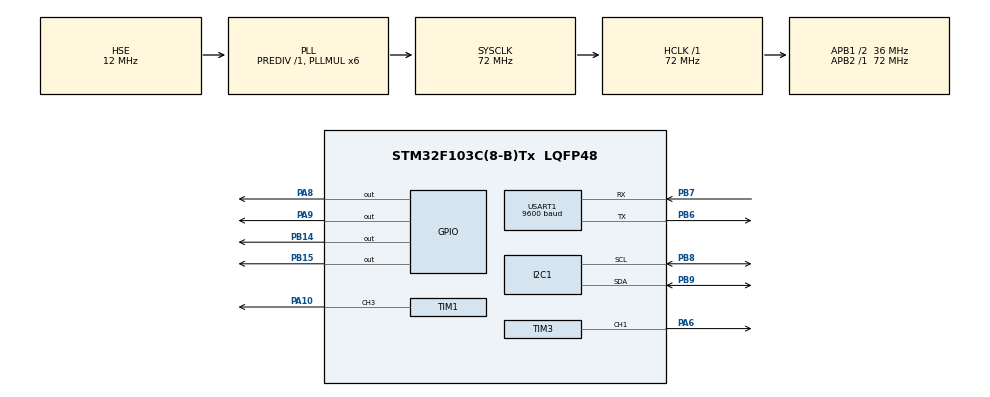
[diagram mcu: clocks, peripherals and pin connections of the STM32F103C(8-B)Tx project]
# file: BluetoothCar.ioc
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I2C1.I2C_Mode=I2C_Fast
Mcu.Family=STM32F1
Mcu.Name=STM32F103C(8-B)Tx
Mcu.Package=LQFP48
NVIC.PriorityGroup=NVIC_PRIORITYGROUP_4
NVIC.TIM3_IRQn=true\:0\:0\:false\:false\:true\:true\:true\:true
NVIC.USART1_IRQn=true\:15\:0\:true\:false\:true\:true\:true\:true
PA10.Signal=S_TIM1_CH3
PA13.Mode=Serial_Wire
PA13.Signal=SYS_JTMS-SWDIO
PA14.Mode=Serial_Wire
PA14.Signal=SYS_JTCK-SWCLK
PA6.Signal=S_TIM3_CH1
PA8.Signal=GPIO_Output
PA9.Signal=GPIO_Output
PB14.Signal=GPIO_Output
PB15.Signal=GPIO_Output
PB6.Mode=Asynchronous
PB6.Signal=USART1_TX
PB7.Mode=Asynchronous
PB7.Signal=USART1_RX
PB8.Mode=I2C
PB8.Signal=I2C1_SCL
PB9.Mode=I2C
PB9.Signal=I2C1_SDA
PD0-OSC_IN.Mode=HSE-External-Oscillator
PD0-OSC_IN.Signal=RCC_OSC_IN
PD1-OSC_OUT.Mode=HSE-External-Oscillator
PD1-OSC_OUT.Signal=RCC_OSC_OUT
ProjectManager.HeapSize=0x200
ProjectManager.StackSize=0x400
ProjectManager.TargetToolchain=STM32CubeIDE
RCC.AHBFreq_Value=72000000
RCC.APB1CLKDivider=RCC_HCLK_DIV2
RCC.APB1Freq_Value=36000000
RCC.APB1TimFreq_Value=72000000
RCC.APB2Freq_Value=72000000
RCC.APB2TimFreq_Value=72000000
RCC.HCLKFreq_Value=72000000
RCC.HSE_VALUE=12000000
RCC.PLLMUL=RCC_PLL_MUL6
RCC.PLLSourceVirtual=RCC_PLLSOURCE_HSE
RCC.SYSCLKFreq_VALUE=72000000
RCC.SYSCLKSource=RCC_SYSCLKSOURCE_PLLCLK
RCC.USBFreq_Value=72000000
SH.S_TIM1_CH3.0=TIM1_CH3,PWM Generation3 CH3
SH.S_TIM3_CH1.0=TIM3_CH1,PWM Generation1 CH1
TIM1.Channel-PWM\ Generation3\ CH3=TIM_CHANNEL_3
TIM1.OCFastMode_PWM-PWM\ Generation3\ CH3=TIM_OCFAST_ENABLE
TIM1.Period=100
TIM1.Prescaler=72-1
TIM3.Channel-PWM\ Generation1\ CH1=TIM_CHANNEL_1
TIM3.OCFastMode_PWM-PWM\ Generation1\ CH1=TIM_OCFAST_ENABLE
TIM3.Period=100
TIM3.Prescaler=72-1
USART1.BaudRate=9600
USART1.VirtualMode=VM_ASYNC
VP_TIM1_VS_ClockSourceINT.Mode=Internal
VP_TIM3_VS_ClockSourceINT.Mode=Internal
board=custom

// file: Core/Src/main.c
/* USER CODE BEGIN Header */
/**
  ******************************************************************************
  * @file           : main.c
  * @brief          : Main program body
  ******************************************************************************
  * @attention
  *
  * Copyright (c) 2022 STMicroelectronics.
  * All rights reserved.
  *
  * This software is licensed under terms that can be found in the LICENSE file
  * in the root directory of this software component.
  * If no LICENSE file comes with this software, it is provided AS-IS.
  *
  ******************************************************************************
  */
/* USER CODE END Header */
#include "main.h"
#include "ssd1306.h"
#include "stm32f1xx_hal_conf.h"
#include "stm32f1xx_it.h"

I2C_HandleTypeDef hi2c1;

TIM_HandleTypeDef htim1;
TIM_HandleTypeDef htim3;

UART_HandleTypeDef huart1;

/* USER CODE BEGIN PV */
uint8_t r;

const unsigned char photo1[] = {
	0x00 , 0x00 , 0x00 , 0x00 , 0x00 , 0x00 , 0x00 , 0x00 , 0x00 , 0xc0 , 0x00 , 0x00 , 0x00 , 0x00 , 0x00 , 0x00 ,
	0x00 , 0x00 , 0x00 , 0x00 , 0x00 , 0x00 , 0x00 , 0x00 , 0x01 , 0x20 , 0x00 , 0x00 , 0x00 , 0x00 , 0x00 , 0x00 ,
	0x00 , 0x00 , 0x00 , 0x00 , 0x00 , 0x00 , 0x00 , 0x00 , 0x02 , 0x10 , 0x00 , 0x00 , 0x00 , 0x00 , 0x00 , 0x00 ,
	0x00 , 0x00 , 0x00 , 0x00 , 0x00 , 0x00 , 0x00 , 0x00 , 0x04 , 0x10 , 0x00 , 0x00 , 0x00 , 0x00 , 0x00 , 0x00 ,
	0x00 , 0x00 , 0x00 , 0x00 , 0x00 , 0x00 , 0x00 , 0x00 , 0x78 , 0x08 , 0x00 , 0x00 , 0x00 , 0x00 , 0x00 , 0x00 ,
	0x00 , 0x00 , 0x00 , 0x00 , 0x00 , 0x00 , 0x00 , 0x07 , 0x80 , 0x08 , 0x00 , 0x00 , 0x00 , 0x00 , 0x00 , 0x00 ,
	0x00 , 0x00 , 0x00 , 0x00 , 0x00 , 0x00 , 0x00 , 0x18 , 0x00 , 0x04 , 0x00 , 0x00 , 0x00 , 0x00 , 0x00 , 0x00 ,
	0x00 , 0x00 , 0x00 , 0x00 , 0x00 , 0x00 , 0x18 , 0x20 , 0x00 , 0x02 , 0x00 , 0x00 , 0x00 , 0x00 , 0x00 , 0x07 ,
	0x00 , 0x00 , 0x00 , 0x00 , 0x00 , 0x00 , 0x26 , 0x40 , 0x00 , 0x01 , 0x9e , 0x00 , 0x00 , 0x00 , 0x00 , 0x78 ,
	0x00 , 0x00 , 0x00 , 0x00 , 0x00 , 0x00 , 0x41 , 0x80 , 0x00 , 0x00 , 0x61 , 0x00 , 0x00 , 0x00 , 0x07 , 0x80 ,
	0x00 , 0x00 , 0x00 , 0x00 , 0x00 , 0x00 , 0x40 , 0x00 , 0x00 , 0x00 , 0x24 , 0x80 , 0x00 , 0x00 , 0xf8 , 0x00 ,
	0x00 , 0x00 , 0x00 , 0x00 , 0x00 , 0x00 , 0x40 , 0x00 , 0x00 , 0x00 , 0x51 , 0x80 , 0x00 , 0x1f , 0x00 , 0x00 ,
	0x00 , 0x00 , 0x00 , 0x00 , 0x00 , 0x00 , 0x40 , 0x00 , 0x00 , 0x18 , 0x4c , 0x80 , 0x01 , 0xe0 , 0x00 , 0x00 ,
	0x00 , 0x00 , 0x00 , 0x00 , 0x00 , 0x00 , 0x20 , 0x00 , 0x00 , 0x18 , 0x8c , 0x80 , 0x1e , 0x00 , 0x00 , 0x00 ,
	0x00 , 0x00 , 0x00 , 0x00 , 0x00 , 0x00 , 0x20 , 0x00 , 0x00 , 0x00 , 0x80 , 0x81 , 0xe0 , 0x00 , 0x00 , 0x00 ,
	0x00 , 0x00 , 0x00 , 0x00 , 0x00 , 0x00 , 0x20 , 0x03 , 0x00 , 0x40 , 0x81 , 0x1e , 0x00 , 0x00 , 0x00 , 0x00 ,
	0x00 , 0x00 , 0x00 , 0x00 , 0x00 , 0x00 , 0x10 , 0x03 , 0x13 , 0xc0 , 0x01 , 0xe0 , 0x00 , 0x00 , 0x00 , 0x00 ,
	0x00 , 0x00 , 0x00 , 0x00 , 0x00 , 0x00 , 0x10 , 0x00 , 0x0c , 0x00 , 0x0e , 0x00 , 0x00 , 0x00 , 0x00 , 0x00 ,
	0x00 , 0x00 , 0x00 , 0x00 , 0x00 , 0x00 , 0x20 , 0x00 , 0x00 , 0x03 , 0xf0 , 0x00 , 0x00 , 0x00 , 0x00 , 0x00 ,
	0x00 , 0x00 , 0x00 , 0x00 , 0x00 , 0x00 , 0x20 , 0x00 , 0x00 , 0x7c , 0x00 , 0x00 , 0x00 , 0x00 , 0x00 , 0x00 ,
	0x00 , 0x00 , 0x00 , 0x00 , 0x00 , 0x00 , 0x40 , 0x00 , 0x07 , 0x80 , 0x00 , 0x00 , 0x00 , 0x00 , 0x00 , 0x00 ,
	0x00 , 0x00 , 0x00 , 0x00 , 0x00 , 0x00 , 0x40 , 0x00 , 0x38 , 0x00 , 0x00 , 0x00 , 0x00 , 0x00 , 0x00 , 0x00 ,
	0x00 , 0x00 , 0x00 , 0x00 , 0x00 , 0x00 , 0x40 , 0x00 , 0x40 , 0x00 , 0x00 , 0x00 , 0x00 , 0x00 , 0x00 , 0x00 ,
	0x00 , 0x00 , 0x00 , 0x00 , 0x00 , 0x00 , 0x80 , 0x00 , 0x20 , 0x00 , 0x00 , 0x00 , 0x00 , 0x00 , 0x00 , 0x00 ,
	0x00 , 0x00 , 0x00 , 0x00 , 0x00 , 0x00 , 0x9f , 0x80 , 0x20 , 0x00 , 0x00 , 0x00 , 0x00 , 0x00 , 0x00 , 0x00 ,
	0x00 , 0x00 , 0x00 , 0x00 , 0x00 , 0x01 , 0xe0 , 0x60 , 0x20 , 0x00 , 0x00 , 0x00 , 0x00 , 0x00 , 0x00 , 0x00 ,
	0x00 , 0x00 , 0x00 , 0x00 , 0x00 , 0x3e , 0x00 , 0x18 , 0x20 , 0x00 , 0x00 , 0x00 , 0x00 , 0x00 , 0x00 , 0x00 ,
	0x00 , 0x00 , 0x00 , 0x00 , 0x07 , 0xc0 , 0x7f , 0x07 , 0xc0 , 0x00 , 0x00 , 0x00 , 0x00 , 0x00 , 0x00 , 0x00 ,
	0x00 , 0x00 , 0x00 , 0x00 , 0x78 , 0x00 , 0x7f , 0x80 , 0x00 , 0x00 , 0x00 , 0x00 , 0x00 , 0x00 , 0x00 , 0x00 ,
	0x00 , 0x00 , 0x00 , 0x07 , 0x80 , 0x00 , 0x7f , 0x80 , 0x00 , 0x00 , 0x00 , 0x00 , 0x00 , 0x00 , 0x00 , 0x00 ,
	0x00 , 0x00 , 0x00 , 0x78 , 0x00 , 0x00 , 0x7e , 0x00 , 0x00 , 0x00 , 0x00 , 0x00 , 0x00 , 0x00 , 0x00 , 0x00 ,
	0x00 , 0x00 , 0x07 , 0x80 , 0x00 , 0x00 , 0x00 , 0x00 , 0xf0 , 0x00 , 0x00 , 0x00 , 0x00 , 0x00 , 0x00 , 0x00 ,
	0x00 , 0x00 , 0x78 , 0x00 , 0x00 , 0x00 , 0x00 , 0x70 , 0xf8 , 0x00 , 0x00 , 0x00 , 0x00 , 0x00 , 0x00 , 0x00 ,
	0x00 , 0x07 , 0x80 , 0x00 , 0x00 , 0x00 , 0x00 , 0xf0 , 0xfc , 0x00 , 0x00 , 0x00 , 0x00 , 0x00 , 0x00 , 0x00 ,
	0x00 , 0x78 , 0x00 , 0x00 , 0x00 , 0x00 , 0x01 , 0xf0 , 0xfe , 0x00 , 0x00 , 0x00 , 0x00 , 0x00 , 0x00 , 0x00 ,
	0x07 , 0x80 , 0x00 , 0x00 , 0x00 , 0x00 , 0x03 , 0xe0 , 0xff , 0x00 , 0x00 , 0x00 , 0x00 , 0x00 , 0x00 , 0x00 ,
	0x78 , 0x00 , 0x00 , 0x00 , 0x00 , 0x00 , 0x07 , 0xe0 , 0xff , 0x00 , 0x00 , 0x00 , 0x00 , 0x00 , 0x00 , 0x00 ,
	0x80 , 0x00 , 0x00 , 0x00 , 0x00 , 0x00 , 0x07 , 0xe0 , 0xfc , 0x00 , 0x00 , 0x00 , 0x00 , 0x00 , 0x00 , 0x00 ,
	0x00 , 0x00 , 0x00 , 0x00 , 0x00 , 0x00 , 0x03 , 0xc0 , 0xf0 , 0x00 , 0x00 , 0x00 , 0x00 , 0x00 , 0x00 , 0x00 ,
	0x00 , 0x00 , 0x00 , 0x00 , 0x00 , 0x00 , 0x00 , 0xc0 , 0xc0 , 0x00 , 0x00 , 0x00 , 0x00 , 0x00 , 0x00 , 0x00 ,
};
const unsigned char photo2[] = {
	0x00 , 0x00 , 0x00 , 0x00 , 0x00 , 0x00 , 0x00 , 0x00 , 0x00 , 0xc0 , 0x00 , 0x00 , 0x00 , 0x00 , 0x00 , 0x00 ,
	0x00 , 0x00 , 0x00 , 0x00 , 0x00 , 0x00 , 0x00 , 0x00 , 0x01 , 0x20 , 0x00 , 0x00 , 0x00 , 0x00 , 0x00 , 0x00 ,
	0x00 , 0x00 , 0x00 , 0x00 , 0x00 , 0x00 , 0x00 , 0x00 , 0x02 , 0x10 , 0x00 , 0x00 , 0x00 , 0x00 , 0x00 , 0x00 ,
	0x00 , 0x00 , 0x00 , 0x00 , 0x00 , 0x00 , 0x00 , 0x00 , 0x04 , 0x10 , 0x03 , 0xc0 , 0x00 , 0x00 , 0x00 , 0x00 ,
	0x00 , 0x00 , 0x00 , 0x00 , 0x00 , 0x00 , 0x00 , 0x00 , 0x78 , 0x08 , 0x03 , 0xc0 , 0x00 , 0x00 , 0x00 , 0x00 ,
	0x00 , 0x00 , 0x00 , 0x00 , 0x00 , 0x00 , 0x00 , 0x07 , 0x80 , 0x08 , 0x03 , 0xc0 , 0x00 , 0x00 , 0x00 , 0x00 ,
	0x00 , 0x00 , 0x00 , 0x00 , 0x00 , 0x00 , 0x00 , 0x18 , 0x00 , 0x04 , 0x03 , 0xc0 , 0x00 , 0x00 , 0x00 , 0x00 ,
	0x00 , 0x00 , 0x00 , 0x00 , 0x00 , 0x00 , 0x18 , 0x20 , 0x00 , 0x02 , 0x03 , 0xc1 , 0x80 , 0x00 , 0x00 , 0x07 ,
	0x00 , 0x00 , 0x00 , 0x00 , 0x00 , 0x00 , 0x26 , 0x40 , 0x00 , 0x01 , 0x83 , 0xc3 , 0xc0 , 0x00 , 0x00 , 0x78 ,
	0x00 , 0x00 , 0x00 , 0x00 , 0x00 , 0x00 , 0x41 , 0x80 , 0x00 , 0x00 , 0x43 , 0x87 , 0xc0 , 0x00 , 0x07 , 0x80 ,
	0x00 , 0x00 , 0x00 , 0x00 , 0x00 , 0x00 , 0x40 , 0x00 , 0x00 , 0x00 , 0x21 , 0x8f , 0xe0 , 0x00 , 0xf8 , 0x00 ,
	0x00 , 0x00 , 0x00 , 0x00 , 0x00 , 0x00 , 0x40 , 0x00 , 0x00 , 0x00 , 0x10 , 0x1f , 0xe0 , 0x1f , 0x00 , 0x00 ,
	0x00 , 0x00 , 0x00 , 0x00 , 0x00 , 0x00 , 0x40 , 0x00 , 0x00 , 0x18 , 0x08 , 0x1f , 0x81 , 0xe0 , 0x00 , 0x00 ,
	0x00 , 0x00 , 0x00 , 0x00 , 0x00 , 0x00 , 0x20 , 0x00 , 0x00 , 0x18 , 0x04 , 0x1c , 0x1e , 0x00 , 0x00 , 0x00 ,
	0x00 , 0x00 , 0x00 , 0x00 , 0x00 , 0x00 , 0x20 , 0x00 , 0x00 , 0x00 , 0x02 , 0x01 , 0xe0 , 0x00 , 0x00 , 0x00 ,
	0x00 , 0x00 , 0x00 , 0x00 , 0x00 , 0x00 , 0x20 , 0x73 , 0x00 , 0x40 , 0x01 , 0x1e , 0x00 , 0x00 , 0x00 , 0x00 ,
	0x00 , 0x00 , 0x00 , 0x00 , 0x00 , 0x00 , 0x10 , 0xab , 0x13 , 0xc0 , 0x01 , 0xe0 , 0x00 , 0x00 , 0x00 , 0x00 ,
	0x00 , 0x00 , 0x00 , 0x00 , 0x00 , 0x00 , 0x11 , 0x08 , 0x0c , 0x00 , 0x00 , 0x80 , 0x00 , 0x00 , 0x00 , 0x00 ,
	0x00 , 0x00 , 0x00 , 0x00 , 0x00 , 0x00 , 0x21 , 0x94 , 0x00 , 0x03 , 0x00 , 0xbf , 0xe0 , 0x00 , 0x00 , 0x00 ,
	0x00 , 0x00 , 0x00 , 0x00 , 0x00 , 0x00 , 0x22 , 0x64 , 0x00 , 0x7c , 0xc0 , 0xbf , 0xe0 , 0x00 , 0x00 , 0x00 ,
	0x00 , 0x00 , 0x00 , 0x00 , 0x00 , 0x00 , 0x42 , 0x64 , 0x07 , 0x80 , 0x3f , 0x3f , 0xc0 , 0x00 , 0x00 , 0x00 ,
	0x00 , 0x00 , 0x00 , 0x00 , 0x00 , 0x00 , 0x40 , 0x04 , 0x38 , 0x00 , 0x00 , 0x3f , 0xc0 , 0x00 , 0x00 , 0x00 ,
	0x00 , 0x00 , 0x00 , 0x00 , 0x00 , 0x00 , 0x40 , 0x0f , 0xc0 , 0x00 , 0x00 , 0x1f , 0x80 , 0x00 , 0x00 , 0x00 ,
	0x00 , 0x00 , 0x00 , 0x00 , 0x00 , 0x00 , 0x80 , 0x70 , 0x00 , 0x00 , 0x00 , 0x0f , 0x80 , 0x00 , 0x00 , 0x00 ,
	0x00 , 0x00 , 0x00 , 0x00 , 0x00 , 0x00 , 0x9f , 0x80 , 0x00 , 0x00 , 0x00 , 0x07 , 0x00 , 0x00 , 0x00 , 0x00 ,
	0x00 , 0x00 , 0x00 , 0x00 , 0x00 , 0x01 , 0xe0 , 0x00 , 0x00 , 0x00 , 0x00 , 0x03 , 0x00 , 0x00 , 0x00 , 0x00 ,
	0x00 , 0x00 , 0x00 , 0x00 , 0x00 , 0x3e , 0x00 , 0x00 , 0x00 , 0x00 , 0x00 , 0x00 , 0x00 , 0x00 , 0x00 , 0x00 ,
	0x00 , 0x00 , 0x00 , 0x00 , 0x07 , 0xc0 , 0x00 , 0x00 , 0x00 , 0x00 , 0x00 , 0x00 , 0x00 , 0x00 , 0x00 , 0x00 ,
	0x00 , 0x00 , 0x00 , 0x00 , 0x78 , 0x00 , 0x00 , 0x00 , 0x00 , 0x00 , 0x00 , 0x00 , 0x00 , 0x00 , 0x00 , 0x00 ,
	0x00 , 0x00 , 0x00 , 0x07 , 0x80 , 0x00 , 0x00 , 0x00 , 0x00 , 0x00 , 0x00 , 0x00 , 0x00 , 0x00 , 0x00 , 0x00 ,
	0x00 , 0x00 , 0x00 , 0x78 , 0x00 , 0x00 , 0x00 , 0x00 , 0x00 , 0x00 , 0x00 , 0x00 , 0x00 , 0x00 , 0x00 , 0x00 ,
	0x00 , 0x00 , 0x07 , 0x80 , 0x00 , 0x00 , 0x00 , 0x00 , 0x00 , 0x00 , 0x00 , 0x00 , 0x00 , 0x00 , 0x00 , 0x00 ,
	0x00 , 0x00 , 0x78 , 0x00 , 0x00 , 0x00 , 0x00 , 0x00 , 0x00 , 0x00 , 0x00 , 0x00 , 0x00 , 0x00 , 0x00 , 0x00 ,
	0x00 , 0x07 , 0x80 , 0x00 , 0x00 , 0x00 , 0x00 , 0x00 , 0x00 , 0x00 , 0x00 , 0x00 , 0x00 , 0x00 , 0x00 , 0x00 ,
	0x00 , 0x78 , 0x00 , 0x00 , 0x00 , 0x00 , 0x00 , 0x00 , 0x00 , 0x00 , 0x00 , 0x00 , 0x00 , 0x00 , 0x00 , 0x00 ,
	0x07 , 0x80 , 0x00 , 0x00 , 0x00 , 0x00 , 0x00 , 0x00 , 0x00 , 0x00 , 0x00 , 0x00 , 0x00 , 0x00 , 0x00 , 0x00 ,
	0x78 , 0x00 , 0x00 , 0x00 , 0x00 , 0x00 , 0x00 , 0x00 , 0x00 , 0x00 , 0x00 , 0x00 , 0x00 , 0x00 , 0x00 , 0x00 ,
	0x80 , 0x00 , 0x00 , 0x00 , 0x00 , 0x00 , 0x00 , 0x00 , 0x00 , 0x00 , 0x00 , 0x00 , 0x00 , 0x00 , 0x00 , 0x00 ,
	0x00 , 0x00 , 0x00 , 0x00 , 0x00 , 0x00 , 0x00 , 0x00 , 0x00 , 0x00 , 0x00 , 0x00 , 0x00 , 0x00 , 0x00 , 0x00 ,
	0x00 , 0x00 , 0x00 , 0x00 , 0x00 , 0x00 , 0x00 , 0x00 , 0x00 , 0x00 , 0x00 , 0x00 , 0x00 , 0x00 , 0x00 , 0x00 ,
};
const unsigned char photo3[] = {
	0x00 , 0x00 , 0x00 , 0x00 , 0x00 , 0x00 , 0x00 , 0x00 , 0x00 , 0xc0 , 0x00 , 0x00 , 0x00 , 0x00 , 0x00 , 0x00 ,
	0x00 , 0x00 , 0x00 , 0x00 , 0x00 , 0x00 , 0x00 , 0x00 , 0x01 , 0x20 , 0x00 , 0x00 , 0x00 , 0x00 , 0x00 , 0x00 ,
	0x00 , 0x00 , 0x00 , 0x00 , 0x00 , 0x00 , 0x00 , 0x00 , 0x02 , 0x10 , 0x00 , 0x00 , 0x00 , 0x00 , 0x00 , 0x00 ,
	0x00 , 0x00 , 0x00 , 0x00 , 0x00 , 0x00 , 0x00 , 0x00 , 0x04 , 0x10 , 0x00 , 0x00 , 0x00 , 0x00 , 0x00 , 0x00 ,
	0x00 , 0x00 , 0x00 , 0x00 , 0x00 , 0x00 , 0x00 , 0x00 , 0x78 , 0x08 , 0x00 , 0x00 , 0x00 , 0x00 , 0x00 , 0x00 ,
	0x00 , 0x00 , 0x00 , 0x00 , 0x00 , 0x00 , 0x00 , 0x07 , 0x80 , 0x08 , 0x00 , 0x00 , 0x00 , 0x00 , 0x00 , 0x00 ,
	0x00 , 0x00 , 0x00 , 0x00 , 0x00 , 0x00 , 0x00 , 0x18 , 0x00 , 0x04 , 0x00 , 0x00 , 0x00 , 0x00 , 0x00 , 0x00 ,
	0x00 , 0x00 , 0x00 , 0x00 , 0x00 , 0x00 , 0x18 , 0x20 , 0x00 , 0x02 , 0x00 , 0x00 , 0x00 , 0x00 , 0x00 , 0x07 ,
	0x00 , 0x00 , 0x00 , 0x00 , 0x00 , 0x00 , 0x26 , 0x40 , 0x00 , 0x01 , 0x80 , 0x00 , 0x00 , 0x00 , 0x00 , 0x78 ,
	0x00 , 0x00 , 0x00 , 0x00 , 0x00 , 0x00 , 0x41 , 0x80 , 0x00 , 0x00 , 0x40 , 0x00 , 0x00 , 0x00 , 0x07 , 0x80 ,
	0x00 , 0x00 , 0x00 , 0x00 , 0x00 , 0x00 , 0x40 , 0x00 , 0x00 , 0x00 , 0x20 , 0x00 , 0x00 , 0x00 , 0xf8 , 0x00 ,
	0x00 , 0x00 , 0x00 , 0x00 , 0x00 , 0x00 , 0x40 , 0x00 , 0x00 , 0x00 , 0x10 , 0x00 , 0x00 , 0x1f , 0x00 , 0x00 ,
	0x00 , 0x00 , 0x00 , 0x00 , 0x00 , 0x00 , 0x40 , 0x00 , 0x00 , 0x18 , 0x08 , 0x00 , 0x01 , 0xe0 , 0x00 , 0x00 ,
	0x00 , 0x00 , 0x00 , 0x00 , 0x00 , 0x00 , 0x20 , 0x00 , 0x00 , 0x18 , 0x04 , 0x00 , 0x1e , 0x00 , 0x00 , 0x00 ,
	0x00 , 0x00 , 0x00 , 0x00 , 0x00 , 0x00 , 0x20 , 0x00 , 0x00 , 0x03 , 0xc2 , 0x01 , 0xe0 , 0x00 , 0x00 , 0x00 ,
	0x00 , 0x00 , 0x00 , 0x00 , 0x00 , 0x00 , 0x20 , 0x03 , 0x00 , 0x43 , 0xc1 , 0x1e , 0x00 , 0x00 , 0x00 , 0x00 ,
	0x00 , 0x00 , 0x00 , 0x00 , 0x00 , 0x00 , 0x10 , 0x03 , 0x13 , 0xc0 , 0x01 , 0xe0 , 0x00 , 0x00 , 0x00 , 0x00 ,
	0x00 , 0x00 , 0x00 , 0x00 , 0x00 , 0x00 , 0x10 , 0x00 , 0x0c , 0x00 , 0x00 , 0x80 , 0x00 , 0x00 , 0x00 , 0x00 ,
	0x00 , 0x00 , 0x00 , 0x00 , 0x00 , 0x00 , 0x20 , 0x1e , 0x00 , 0x03 , 0x00 , 0x80 , 0x00 , 0x00 , 0x00 , 0x00 ,
	0x00 , 0x00 , 0x00 , 0x00 , 0x00 , 0x00 , 0x20 , 0x1e , 0x00 , 0x7c , 0xc0 , 0x80 , 0x00 , 0x00 , 0x00 , 0x00 ,
	0x00 , 0x00 , 0x00 , 0x00 , 0x00 , 0x00 , 0x40 , 0x00 , 0x07 , 0x80 , 0x3f , 0x00 , 0x00 , 0x00 , 0x00 , 0x00 ,
	0x00 , 0x00 , 0x00 , 0x00 , 0x00 , 0x00 , 0x40 , 0x00 , 0x38 , 0x00 , 0x00 , 0x00 , 0x00 , 0x00 , 0x00 , 0x00 ,
	0x00 , 0x00 , 0x00 , 0x00 , 0x00 , 0x00 , 0x40 , 0x00 , 0x40 , 0x00 , 0x00 , 0x00 , 0x00 , 0x00 , 0x00 , 0x00 ,
	0x00 , 0x00 , 0x00 , 0x00 , 0x00 , 0x00 , 0x80 , 0x00 , 0x20 , 0x00 , 0x00 , 0x00 , 0x00 , 0x00 , 0x00 , 0x00 ,
	0x00 , 0x00 , 0x00 , 0x00 , 0x00 , 0x00 , 0x9f , 0x80 , 0x20 , 0x00 , 0x00 , 0x00 , 0x00 , 0x00 , 0x00 , 0x00 ,
	0x00 , 0x00 , 0x00 , 0x00 , 0x00 , 0x01 , 0xe0 , 0x60 , 0x20 , 0x00 , 0x00 , 0x00 , 0x00 , 0x00 , 0x00 , 0x00 ,
	0x00 , 0x00 , 0x00 , 0x00 , 0x00 , 0x3e , 0x00 , 0x18 , 0x20 , 0x00 , 0x00 , 0x00 , 0x00 , 0x00 , 0x00 , 0x00 ,
	0x00 , 0x00 , 0x00 , 0x00 , 0x07 , 0xc0 , 0x00 , 0x07 , 0xc0 , 0x00 , 0x00 , 0x00 , 0x00 , 0x00 , 0x00 , 0x00 ,
	0x00 , 0x00 , 0x00 , 0x00 , 0x78 , 0x00 , 0x00 , 0x00 , 0x00 , 0x00 , 0x00 , 0x00 , 0x00 , 0x00 , 0x00 , 0x00 ,
	0x00 , 0x00 , 0x00 , 0x07 , 0x80 , 0x00 , 0x00 , 0x00 , 0x00 , 0x00 , 0x00 , 0x00 , 0x00 , 0x00 , 0x00 , 0x00 ,
	0x00 , 0x00 , 0x00 , 0x78 , 0x00 , 0x00 , 0x00 , 0x00 , 0x00 , 0x00 , 0x00 , 0x00 , 0x00 , 0x00 , 0x00 , 0x00 ,
	0x00 , 0x00 , 0x07 , 0x80 , 0x00 , 0x00 , 0x00 , 0x00 , 0x00 , 0x00 , 0x00 , 0x00 , 0x00 , 0x00 , 0x00 , 0x00 ,
	0x00 , 0x00 , 0x78 , 0x00 , 0x00 , 0x00 , 0x00 , 0x00 , 0x00 , 0x00 , 0x00 , 0x00 , 0x00 , 0x00 , 0x00 , 0x00 ,
	0x00 , 0x07 , 0x80 , 0x00 , 0x00 , 0x00 , 0x00 , 0x00 , 0x00 , 0x00 , 0x00 , 0x00 , 0x00 , 0x00 , 0x00 , 0x00 ,
	0x00 , 0x78 , 0x00 , 0x00 , 0x00 , 0x00 , 0x00 , 0x00 , 0x00 , 0x00 , 0x00 , 0x00 , 0x00 , 0x00 , 0x00 , 0x00 ,
	0x07 , 0x80 , 0x00 , 0x00 , 0x00 , 0x00 , 0x00 , 0x00 , 0x00 , 0x00 , 0x00 , 0x00 , 0x00 , 0x00 , 0x00 , 0x00 ,
	0x78 , 0x00 , 0x00 , 0x00 , 0x00 , 0x00 , 0x00 , 0x00 , 0x00 , 0x00 , 0x00 , 0x00 , 0x00 , 0x00 , 0x00 , 0x00 ,
	0x80 , 0x00 , 0x00 , 0x00 , 0x00 , 0x00 , 0x00 , 0x00 , 0x00 , 0x00 , 0x00 , 0x00 , 0x00 , 0x00 , 0x00 , 0x00 ,
	0x00 , 0x00 , 0x00 , 0x00 , 0x00 , 0x00 , 0x00 , 0x00 , 0x00 , 0x00 , 0x00 , 0x00 , 0x00 , 0x00 , 0x00 , 0x00 ,
	0x00 , 0x00 , 0x00 , 0x00 , 0x00 , 0x00 , 0x00 , 0x00 , 0x00 , 0x00 , 0x00 , 0x00 , 0x00 , 0x00 , 0x00 , 0x00 ,
};
const unsigned char photo4[] = {
	0x00 , 0x00 , 0x00 , 0x00 , 0x00 , 0x00 , 0x00 , 0x00 , 0x00 , 0x00 , 0x00 , 0x00 , 0x00 , 0x00 , 0x00 , 0x00 ,
	0x00 , 0x00 , 0x00 , 0x00 , 0x00 , 0x00 , 0x00 , 0x00 , 0x00 , 0xc0 , 0x00 , 0x00 , 0x00 , 0x00 , 0x00 , 0x00 ,
	0x00 , 0x00 , 0x00 , 0x00 , 0x00 , 0x00 , 0x00 , 0x00 , 0x01 , 0x20 , 0x00 , 0x00 , 0x00 , 0x00 , 0x00 , 0x00 ,
	0x00 , 0x00 , 0x00 , 0x00 , 0x00 , 0x00 , 0x00 , 0x00 , 0x02 , 0x10 , 0x00 , 0x00 , 0x00 , 0x00 , 0x00 , 0x00 ,
	0x00 , 0x00 , 0x00 , 0x00 , 0x00 , 0x00 , 0x00 , 0x00 , 0x04 , 0x10 , 0x00 , 0x00 , 0x00 , 0x00 , 0x00 , 0x00 ,
	0x00 , 0x00 , 0x00 , 0x00 , 0x00 , 0x00 , 0x00 , 0x00 , 0x78 , 0x08 , 0x00 , 0x00 , 0x00 , 0x00 , 0x00 , 0x00 ,
	0x00 , 0x00 , 0x00 , 0x00 , 0x00 , 0x00 , 0x00 , 0x07 , 0x80 , 0x08 , 0x00 , 0x00 , 0x00 , 0x00 , 0x00 , 0x00 ,
	0x00 , 0x00 , 0x00 , 0x00 , 0x00 , 0x00 , 0x00 , 0x18 , 0x00 , 0x04 , 0x00 , 0x00 , 0x00 , 0x00 , 0x00 , 0x07 ,
	0x00 , 0x00 , 0x00 , 0x00 , 0x00 , 0x00 , 0x18 , 0x20 , 0x00 , 0x02 , 0x00 , 0x00 , 0x00 , 0x00 , 0x00 , 0x78 ,
	0x00 , 0x00 , 0x00 , 0x00 , 0x00 , 0x00 , 0x26 , 0x40 , 0x00 , 0x01 , 0x80 , 0x00 , 0x00 , 0x00 , 0x07 , 0x80 ,
	0x00 , 0x00 , 0x00 , 0x00 , 0x00 , 0x00 , 0x41 , 0x80 , 0x00 , 0x00 , 0x40 , 0x00 , 0x00 , 0x00 , 0xf8 , 0x00 ,
	0x00 , 0x00 , 0x00 , 0x00 , 0x00 , 0x00 , 0x40 , 0x00 , 0x00 , 0x00 , 0x20 , 0x00 , 0x00 , 0x1f , 0x00 , 0x00 ,
	0x00 , 0x00 , 0x00 , 0x00 , 0x00 , 0x00 , 0x40 , 0x00 , 0x00 , 0x00 , 0x10 , 0x00 , 0x01 , 0xe0 , 0x00 , 0x00 ,
	0x00 , 0x00 , 0x00 , 0x00 , 0x00 , 0x00 , 0x40 , 0x00 , 0x00 , 0x18 , 0x08 , 0x00 , 0x1e , 0x00 , 0x00 , 0x00 ,
	0x00 , 0x00 , 0x00 , 0x00 , 0x00 , 0x00 , 0x20 , 0x00 , 0x00 , 0x18 , 0x04 , 0x01 , 0xe0 , 0x00 , 0x00 , 0x00 ,
	0x00 , 0x00 , 0x00 , 0x00 , 0x00 , 0x00 , 0x20 , 0x00 , 0x00 , 0x03 , 0xc2 , 0x1e , 0x00 , 0x00 , 0x00 , 0x00 ,
	0x00 , 0x00 , 0x00 , 0x00 , 0x00 , 0x00 , 0x20 , 0x03 , 0x00 , 0x43 , 0xc1 , 0xe0 , 0x00 , 0x00 , 0x00 , 0x00 ,
	0x00 , 0x00 , 0x00 , 0x00 , 0x00 , 0x00 , 0x10 , 0x03 , 0x13 , 0xc0 , 0x00 , 0x80 , 0x00 , 0x00 , 0x00 , 0x00 ,
	0x00 , 0x00 , 0x00 , 0x00 , 0x00 , 0x00 , 0x10 , 0x00 , 0x0c , 0x03 , 0x00 , 0x80 , 0x00 , 0x00 , 0x00 , 0x00 ,
	0x00 , 0x00 , 0x00 , 0x00 , 0x00 , 0x00 , 0x20 , 0x1e , 0x00 , 0x7c , 0xc0 , 0x80 , 0x00 , 0x00 , 0x00 , 0x00 ,
	0x00 , 0x00 , 0x00 , 0x00 , 0x00 , 0x00 , 0x60 , 0x1e , 0x07 , 0x80 , 0x3f , 0x00 , 0x00 , 0x00 , 0x00 , 0x00 ,
	0x00 , 0x00 , 0x00 , 0x00 , 0x00 , 0x00 , 0x40 , 0x00 , 0x38 , 0x00 , 0x00 , 0x00 , 0x00 , 0x00 , 0x00 , 0x00 ,
	0x00 , 0x00 , 0x00 , 0x00 , 0x00 , 0x00 , 0x40 , 0x00 , 0x40 , 0x00 , 0x00 , 0x00 , 0x00 , 0x00 , 0x00 , 0x00 ,
	0x00 , 0x00 , 0x00 , 0x00 , 0x00 , 0x00 , 0x80 , 0x00 , 0x20 , 0x00 , 0x00 , 0x00 , 0x00 , 0x00 , 0x00 , 0x00 ,
	0x00 , 0x00 , 0x00 , 0x00 , 0x00 , 0x00 , 0x9f , 0x80 , 0x20 , 0x00 , 0x00 , 0x00 , 0x00 , 0x00 , 0x00 , 0x00 ,
	0x00 , 0x00 , 0x00 , 0x00 , 0x00 , 0x01 , 0xe0 , 0x60 , 0x20 , 0x00 , 0x00 , 0x00 , 0x00 , 0x00 , 0x00 , 0x00 ,
	0x00 , 0x00 , 0x00 , 0x00 , 0x00 , 0x3e , 0x00 , 0x18 , 0x20 , 0x00 , 0x00 , 0x00 , 0x00 , 0x00 , 0x00 , 0x00 ,
	0x00 , 0x00 , 0x00 , 0x00 , 0x07 , 0xc0 , 0x00 , 0x07 , 0xc0 , 0x00 , 0x00 , 0x00 , 0x00 , 0x00 , 0x00 , 0x00 ,
	0x00 , 0x00 , 0x00 , 0x00 , 0x78 , 0x00 , 0x00 , 0x00 , 0x00 , 0x00 , 0x00 , 0x00 , 0x00 , 0x00 , 0x00 , 0x00 ,
	0x00 , 0x00 , 0x00 , 0x07 , 0x80 , 0x00 , 0x00 , 0x00 , 0x00 , 0x00 , 0x00 , 0x00 , 0x00 , 0x00 , 0x00 , 0x00 ,
	0x00 , 0x00 , 0x00 , 0x78 , 0x00 , 0x00 , 0x00 , 0x00 , 0x00 , 0x00 , 0x00 , 0x00 , 0x00 , 0x00 , 0x00 , 0x00 ,
	0x00 , 0x00 , 0x07 , 0x80 , 0x00 , 0x00 , 0x00 , 0x00 , 0x00 , 0x00 , 0x00 , 0x00 , 0x00 , 0x00 , 0x00 , 0x00 ,
	0x00 , 0x00 , 0x78 , 0x00 , 0x00 , 0x00 , 0x00 , 0x00 , 0x00 , 0x00 , 0x00 , 0x00 , 0x00 , 0x00 , 0x00 , 0x00 ,
	0x00 , 0x07 , 0x80 , 0x00 , 0x00 , 0x00 , 0x00 , 0x00 , 0x00 , 0x00 , 0x00 , 0x00 , 0x00 , 0x00 , 0x00 , 0x00 ,
	0x00 , 0x78 , 0x00 , 0x00 , 0x00 , 0x00 , 0x00 , 0x00 , 0x00 , 0x00 , 0x00 , 0x00 , 0x00 , 0x00 , 0x00 , 0x00 ,
	0x07 , 0x80 , 0x00 , 0x00 , 0x00 , 0x00 , 0x00 , 0x00 , 0x00 , 0x00 , 0x00 , 0x00 , 0x00 , 0x00 , 0x00 , 0x00 ,
	0x78 , 0x00 , 0x00 , 0x00 , 0x00 , 0x00 , 0x00 , 0x00 , 0x00 , 0x00 , 0x00 , 0x00 , 0x00 , 0x00 , 0x00 , 0x00 ,
	0x80 , 0x00 , 0x00 , 0x00 , 0x00 , 0x00 , 0x00 , 0x00 , 0x00 , 0x00 , 0x00 , 0x00 , 0x00 , 0x00 , 0x00 , 0x00 ,
	0x00 , 0x00 , 0x00 , 0x00 , 0x00 , 0x00 , 0x00 , 0x00 , 0x00 , 0x00 , 0x00 , 0x00 , 0x00 , 0x00 , 0x00 , 0x00 ,
	0x00 , 0x00 , 0x00 , 0x00 , 0x00 , 0x00 , 0x00 , 0x00 , 0x00 , 0x00 , 0x00 , 0x00 , 0x00 , 0x00 , 0x00 , 0x00 ,
};
const unsigned char photo5[] = {
	0x00 , 0x00 , 0x00 , 0x00 , 0x00 , 0x00 , 0x00 , 0x00 , 0x00 , 0x00 , 0x00 , 0x00 , 0x00 , 0x00 , 0x00 , 0x00 ,
	0x00 , 0x00 , 0x00 , 0x00 , 0x00 , 0x00 , 0x00 , 0x00 , 0x00 , 0x00 , 0x00 , 0x00 , 0x00 , 0x00 , 0x00 , 0x00 ,
	0x00 , 0x00 , 0x00 , 0x00 , 0x00 , 0x00 , 0x00 , 0x00 , 0x00 , 0xe0 , 0x00 , 0x00 , 0x00 , 0x00 , 0x00 , 0x00 ,
	0x00 , 0x00 , 0x00 , 0x00 , 0x00 , 0x00 , 0x00 , 0x00 , 0x01 , 0x10 , 0x00 , 0x00 , 0x00 , 0x00 , 0x00 , 0x00 ,
	0x00 , 0x00 , 0x00 , 0x00 , 0x00 , 0x00 , 0x00 , 0x00 , 0x02 , 0x08 , 0x00 , 0x00 , 0x00 , 0x00 , 0x00 , 0x00 ,
	0x00 , 0x00 , 0x00 , 0x00 , 0x00 , 0x00 , 0x00 , 0x00 , 0x7c , 0x08 , 0x00 , 0x00 , 0x00 , 0x00 , 0x00 , 0x00 ,
	0x00 , 0x00 , 0x00 , 0x00 , 0x00 , 0x00 , 0x00 , 0x07 , 0x80 , 0x08 , 0x00 , 0x00 , 0x00 , 0x00 , 0x00 , 0x00 ,
	0x00 , 0x00 , 0x00 , 0x00 , 0x00 , 0x00 , 0x00 , 0x18 , 0x00 , 0x04 , 0x00 , 0x00 , 0x00 , 0x00 , 0x00 , 0x07 ,
	0x00 , 0x00 , 0x00 , 0x00 , 0x00 , 0x00 , 0x00 , 0x20 , 0x00 , 0x02 , 0x00 , 0x00 , 0x00 , 0x00 , 0x00 , 0x78 ,
	0x00 , 0x00 , 0x00 , 0x00 , 0x00 , 0x00 , 0x1c , 0x40 , 0x00 , 0x01 , 0x80 , 0x00 , 0x00 , 0x00 , 0x07 , 0x80 ,
	0x00 , 0x00 , 0x00 , 0x00 , 0x00 , 0x00 , 0x23 , 0x80 , 0x00 , 0x00 , 0x40 , 0x00 , 0x00 , 0x00 , 0xf8 , 0x00 ,
	0x00 , 0x00 , 0x00 , 0x00 , 0x00 , 0x00 , 0x40 , 0x00 , 0x00 , 0x00 , 0x20 , 0x00 , 0x00 , 0x1f , 0x00 , 0x00 ,
	0x00 , 0x00 , 0x00 , 0x00 , 0x00 , 0x00 , 0x40 , 0x00 , 0x00 , 0x00 , 0x10 , 0x00 , 0x01 , 0xe0 , 0x00 , 0x00 ,
	0x00 , 0x00 , 0x00 , 0x00 , 0x00 , 0x00 , 0x40 , 0x00 , 0x00 , 0x18 , 0x08 , 0x00 , 0x1e , 0x00 , 0x00 , 0x00 ,
	0x00 , 0x00 , 0x00 , 0x00 , 0x00 , 0x00 , 0x20 , 0x00 , 0x00 , 0x18 , 0x04 , 0x01 , 0xe0 , 0x00 , 0x00 , 0x00 ,
	0x00 , 0x00 , 0x00 , 0x00 , 0x00 , 0x00 , 0x20 , 0x00 , 0x00 , 0x03 , 0xc2 , 0x1e , 0x00 , 0x00 , 0x00 , 0x00 ,
	0x00 , 0x00 , 0x00 , 0x00 , 0x00 , 0x00 , 0x10 , 0x03 , 0x00 , 0x43 , 0xc1 , 0xe0 , 0x00 , 0x00 , 0x00 , 0x00 ,
	0x00 , 0x00 , 0x00 , 0x00 , 0x00 , 0x00 , 0x10 , 0x03 , 0x13 , 0xc0 , 0x00 , 0x80 , 0x00 , 0x00 , 0x00 , 0x00 ,
	0x00 , 0x00 , 0x00 , 0x00 , 0x00 , 0x00 , 0x10 , 0x00 , 0x0c , 0x03 , 0x00 , 0x80 , 0x00 , 0x00 , 0x00 , 0x00 ,
	0x00 , 0x00 , 0x00 , 0x00 , 0x00 , 0x00 , 0x20 , 0x1e , 0x00 , 0x7c , 0xc0 , 0x80 , 0x00 , 0x00 , 0x00 , 0x00 ,
	0x00 , 0x00 , 0x00 , 0x00 , 0x00 , 0x00 , 0x60 , 0x1e , 0x07 , 0x80 , 0x3f , 0x00 , 0x00 , 0x00 , 0x00 , 0x00 ,
	0x00 , 0x00 , 0x00 , 0x00 , 0x00 , 0x00 , 0x40 , 0x00 , 0x38 , 0x00 , 0x00 , 0x00 , 0x00 , 0x00 , 0x00 , 0x00 ,
	0x00 , 0x00 , 0x00 , 0x00 , 0x00 , 0x00 , 0x40 , 0x00 , 0x40 , 0x00 , 0x00 , 0x00 , 0x00 , 0x00 , 0x00 , 0x00 ,
	0x00 , 0x00 , 0x00 , 0x00 , 0x00 , 0x00 , 0x80 , 0x00 , 0x20 , 0x00 , 0x00 , 0x00 , 0x00 , 0x00 , 0x00 , 0x00 ,
	0x00 , 0x00 , 0x00 , 0x00 , 0x00 , 0x00 , 0x9f , 0x80 , 0x20 , 0x00 , 0x00 , 0x00 , 0x00 , 0x00 , 0x00 , 0x00 ,
	0x00 , 0x00 , 0x00 , 0x00 , 0x00 , 0x01 , 0xe0 , 0x60 , 0x20 , 0x00 , 0x00 , 0x00 , 0x00 , 0x00 , 0x00 , 0x00 ,
	0x00 , 0x00 , 0x00 , 0x00 , 0x00 , 0x3e , 0x00 , 0x18 , 0x20 , 0x00 , 0x00 , 0x00 , 0x00 , 0x00 , 0x00 , 0x00 ,
	0x00 , 0x00 , 0x00 , 0x00 , 0x07 , 0xc0 , 0x00 , 0x07 , 0xc0 , 0x00 , 0x00 , 0x00 , 0x00 , 0x00 , 0x00 , 0x00 ,
	0x00 , 0x00 , 0x00 , 0x00 , 0x78 , 0x00 , 0x00 , 0x00 , 0x00 , 0x00 , 0x00 , 0x00 , 0x00 , 0x00 , 0x00 , 0x00 ,
	0x00 , 0x00 , 0x00 , 0x07 , 0x80 , 0x00 , 0x00 , 0x00 , 0x00 , 0x00 , 0x00 , 0x00 , 0x00 , 0x00 , 0x00 , 0x00 ,
	0x00 , 0x00 , 0x00 , 0x78 , 0x00 , 0x00 , 0x00 , 0x00 , 0x00 , 0x00 , 0x00 , 0x00 , 0x00 , 0x00 , 0x00 , 0x00 ,
	0x00 , 0x00 , 0x07 , 0x80 , 0x00 , 0x00 , 0x00 , 0x00 , 0x00 , 0x00 , 0x00 , 0x00 , 0x00 , 0x00 , 0x00 , 0x00 ,
	0x00 , 0x00 , 0x78 , 0x00 , 0x00 , 0x00 , 0x00 , 0x00 , 0x00 , 0x00 , 0x00 , 0x00 , 0x00 , 0x00 , 0x00 , 0x00 ,
	0x00 , 0x07 , 0x80 , 0x00 , 0x00 , 0x00 , 0x00 , 0x00 , 0x00 , 0x00 , 0x00 , 0x00 , 0x00 , 0x00 , 0x00 , 0x00 ,
	0x00 , 0x78 , 0x00 , 0x00 , 0x00 , 0x00 , 0x00 , 0x00 , 0x00 , 0x00 , 0x00 , 0x00 , 0x00 , 0x00 , 0x00 , 0x00 ,
	0x07 , 0x80 , 0x00 , 0x00 , 0x00 , 0x00 , 0x00 , 0x00 , 0x00 , 0x00 , 0x00 , 0x00 , 0x00 , 0x00 , 0x00 , 0x00 ,
	0x78 , 0x00 , 0x00 , 0x00 , 0x00 , 0x00 , 0x00 , 0x00 , 0x00 , 0x00 , 0x00 , 0x00 , 0x00 , 0x00 , 0x00 , 0x00 ,
	0x80 , 0x00 , 0x00 , 0x00 , 0x00 , 0x00 , 0x00 , 0x00 , 0x00 , 0x00 , 0x00 , 0x00 , 0x00 , 0x00 , 0x00 , 0x00 ,
	0x00 , 0x00 , 0x00 , 0x00 , 0x00 , 0x00 , 0x00 , 0x00 , 0x00 , 0x00 , 0x00 , 0x00 , 0x00 , 0x00 , 0x00 , 0x00 ,
	0x00 , 0x00 , 0x00 , 0x00 , 0x00 , 0x00 , 0x00 , 0x00 , 0x00 , 0x00 , 0x00 , 0x00 , 0x00 , 0x00 , 0x00 , 0x00 ,
};

const unsigned char photo6[] = {
	0x00 , 0x00 , 0x00 , 0x00 , 0x00 , 0x00 , 0x00 , 0x00 , 0x00 , 0x00 , 0x00 , 0x00 , 0x00 , 0x00 , 0x00 , 0x00 ,
	0x00 , 0x00 , 0x00 , 0x00 , 0x00 , 0x00 , 0x00 , 0x00 , 0x00 , 0xe0 , 0x00 , 0x00 , 0x00 , 0x00 , 0x00 , 0x00 ,
	0x00 , 0x00 , 0x00 , 0x00 , 0x00 , 0x00 , 0x00 , 0x00 , 0x01 , 0x10 , 0x00 , 0x00 , 0x00 , 0x00 , 0x00 , 0x00 ,
	0x00 , 0x00 , 0x00 , 0x00 , 0x00 , 0x00 , 0x00 , 0x00 , 0x06 , 0x08 , 0x00 , 0x00 , 0x00 , 0x00 , 0x00 , 0x00 ,
	0x00 , 0x00 , 0x00 , 0x00 , 0x00 , 0x00 , 0x00 , 0x00 , 0x78 , 0x08 , 0x00 , 0x00 , 0x00 , 0x00 , 0x00 , 0x00 ,
	0x00 , 0x00 , 0x00 , 0x00 , 0x00 , 0x00 , 0x00 , 0x07 , 0x80 , 0x08 , 0x00 , 0x00 , 0x00 , 0x00 , 0x00 , 0x00 ,
	0x00 , 0x00 , 0x00 , 0x00 , 0x00 , 0x00 , 0x00 , 0x18 , 0x00 , 0x04 , 0x00 , 0x00 , 0x00 , 0x00 , 0x00 , 0x00 ,
	0x00 , 0x00 , 0x00 , 0x00 , 0x00 , 0x00 , 0x00 , 0x20 , 0x00 , 0x02 , 0x00 , 0x00 , 0x00 , 0x00 , 0x00 , 0x07 ,
	0x00 , 0x00 , 0x00 , 0x00 , 0x00 , 0x00 , 0x18 , 0x40 , 0x00 , 0x01 , 0x80 , 0x00 , 0x00 , 0x00 , 0x00 , 0x78 ,
	0x00 , 0x00 , 0x00 , 0x00 , 0x00 , 0x00 , 0x27 , 0x80 , 0x00 , 0x00 , 0x40 , 0x00 , 0x00 , 0x00 , 0x07 , 0x80 ,
	0x00 , 0x00 , 0x00 , 0x00 , 0x00 , 0x00 , 0x40 , 0x00 , 0x00 , 0x00 , 0x20 , 0x00 , 0x00 , 0x00 , 0xf8 , 0x00 ,
	0x00 , 0x00 , 0x00 , 0x00 , 0x00 , 0x00 , 0x40 , 0x00 , 0x00 , 0x00 , 0x10 , 0x00 , 0x00 , 0x1f , 0x00 , 0x00 ,
	0x00 , 0x00 , 0x00 , 0x00 , 0x00 , 0x00 , 0x40 , 0x00 , 0x00 , 0x18 , 0x08 , 0x00 , 0x01 , 0xe0 , 0x00 , 0x00 ,
	0x00 , 0x00 , 0x00 , 0x00 , 0x00 , 0x00 , 0x20 , 0x00 , 0x00 , 0x18 , 0x04 , 0x00 , 0x1e , 0x00 , 0x00 , 0x00 ,
	0x00 , 0x00 , 0x00 , 0x00 , 0x00 , 0x00 , 0x20 , 0x00 , 0x00 , 0x03 , 0xc2 , 0x01 , 0xe0 , 0x00 , 0x00 , 0x00 ,
	0x00 , 0x00 , 0x00 , 0x00 , 0x00 , 0x00 , 0x20 , 0x03 , 0x00 , 0x43 , 0xc1 , 0x1e , 0x00 , 0x00 , 0x00 , 0x00 ,
	0x00 , 0x00 , 0x00 , 0x00 , 0x00 , 0x00 , 0x10 , 0x03 , 0x13 , 0xc0 , 0x01 , 0xe0 , 0x00 , 0x00 , 0x00 , 0x00 ,
	0x00 , 0x00 , 0x00 , 0x00 , 0x00 , 0x00 , 0x10 , 0x00 , 0x0c , 0x00 , 0x00 , 0x80 , 0x00 , 0x00 , 0x00 , 0x00 ,
	0x00 , 0x00 , 0x00 , 0x00 , 0x00 , 0x00 , 0x20 , 0x1e , 0x00 , 0x03 , 0x00 , 0x80 , 0x00 , 0x00 , 0x00 , 0x00 ,
	0x00 , 0x00 , 0x00 , 0x00 , 0x00 , 0x00 , 0x20 , 0x1e , 0x00 , 0x7c , 0xc0 , 0x80 , 0x00 , 0x00 , 0x00 , 0x00 ,
	0x00 , 0x00 , 0x00 , 0x00 , 0x00 , 0x00 , 0x40 , 0x00 , 0x07 , 0x80 , 0x3f , 0x00 , 0x00 , 0x00 , 0x00 , 0x00 ,
	0x00 , 0x00 , 0x00 , 0x00 , 0x00 , 0x00 , 0x40 , 0x00 , 0x38 , 0x00 , 0x00 , 0x00 , 0x00 , 0x00 , 0x00 , 0x00 ,
	0x00 , 0x00 , 0x00 , 0x00 , 0x00 , 0x00 , 0x40 , 0x00 , 0x40 , 0x00 , 0x00 , 0x00 , 0x00 , 0x00 , 0x00 , 0x00 ,
	0x00 , 0x00 , 0x00 , 0x00 , 0x00 , 0x00 , 0x80 , 0x00 , 0x20 , 0x00 , 0x00 , 0x00 , 0x00 , 0x00 , 0x00 , 0x00 ,
	0x00 , 0x00 , 0x00 , 0x00 , 0x00 , 0x00 , 0x9f , 0x80 , 0x20 , 0x00 , 0x00 , 0x00 , 0x00 , 0x00 , 0x00 , 0x00 ,
	0x00 , 0x00 , 0x00 , 0x00 , 0x00 , 0x01 , 0xe0 , 0x60 , 0x20 , 0x00 , 0x00 , 0x00 , 0x00 , 0x00 , 0x00 , 0x00 ,
	0x00 , 0x00 , 0x00 , 0x00 , 0x00 , 0x3e , 0x00 , 0x18 , 0x20 , 0x00 , 0x00 , 0x00 , 0x00 , 0x00 , 0x00 , 0x00 ,
	0x00 , 0x00 , 0x00 , 0x00 , 0x07 , 0xc0 , 0x00 , 0x07 , 0xc0 , 0x00 , 0x00 , 0x00 , 0x00 , 0x00 , 0x00 , 0x00 ,
	0x00 , 0x00 , 0x00 , 0x00 , 0x78 , 0x00 , 0x00 , 0x00 , 0x00 , 0x00 , 0x00 , 0x00 , 0x00 , 0x00 , 0x00 , 0x00 ,
	0x00 , 0x00 , 0x00 , 0x07 , 0x80 , 0x00 , 0x00 , 0x00 , 0x00 , 0x00 , 0x00 , 0x00 , 0x00 , 0x00 , 0x00 , 0x00 ,
	0x00 , 0x00 , 0x00 , 0x78 , 0x00 , 0x00 , 0x00 , 0x00 , 0x00 , 0x00 , 0x00 , 0x00 , 0x00 , 0x00 , 0x00 , 0x00 ,
	0x00 , 0x00 , 0x07 , 0x80 , 0x00 , 0x00 , 0x00 , 0x00 , 0x00 , 0x00 , 0x00 , 0x00 , 0x00 , 0x00 , 0x00 , 0x00 ,
	0x00 , 0x00 , 0x78 , 0x00 , 0x00 , 0x00 , 0x00 , 0x00 , 0x00 , 0x00 , 0x00 , 0x00 , 0x00 , 0x00 , 0x00 , 0x00 ,
	0x00 , 0x07 , 0x80 , 0x00 , 0x00 , 0x00 , 0x00 , 0x00 , 0x00 , 0x00 , 0x00 , 0x00 , 0x00 , 0x00 , 0x00 , 0x00 ,
	0x00 , 0x78 , 0x00 , 0x00 , 0x00 , 0x00 , 0x00 , 0x00 , 0x00 , 0x00 , 0x00 , 0x00 , 0x00 , 0x00 , 0x00 , 0x00 ,
	0x07 , 0x80 , 0x00 , 0x00 , 0x00 , 0x00 , 0x00 , 0x00 , 0x00 , 0x00 , 0x00 , 0x00 , 0x00 , 0x00 , 0x00 , 0x00 ,
	0x78 , 0x00 , 0x00 , 0x00 , 0x00 , 0x00 , 0x00 , 0x00 , 0x00 , 0x00 , 0x00 , 0x00 , 0x00 , 0x00 , 0x00 , 0x00 ,
	0x80 , 0x00 , 0x00 , 0x00 , 0x00 , 0x00 , 0x00 , 0x00 , 0x00 , 0x00 , 0x00 , 0x00 , 0x00 , 0x00 , 0x00 , 0x00 ,
	0x00 , 0x00 , 0x00 , 0x00 , 0x00 , 0x00 , 0x00 , 0x00 , 0x00 , 0x00 , 0x00 , 0x00 , 0x00 , 0x00 , 0x00 , 0x00 ,
	0x00 , 0x00 , 0x00 , 0x00 , 0x00 , 0x00 , 0x00 , 0x00 , 0x00 , 0x00 , 0x00 , 0x00 , 0x00 , 0x00 , 0x00 , 0x00 ,
};
const unsigned char photo7[] = {
	0x00 , 0x00 , 0x00 , 0x00 , 0x00 , 0x00 , 0x00 , 0x00 , 0x00 , 0xc0 , 0x00 , 0x00 , 0x00 , 0x00 , 0x00 , 0x00 ,
	0x00 , 0x00 , 0x00 , 0x00 , 0x00 , 0x00 , 0x00 , 0x00 , 0x01 , 0x20 , 0x00 , 0x00 , 0x00 , 0x00 , 0x00 , 0x00 ,
	0x00 , 0x00 , 0x00 , 0x00 , 0x00 , 0x00 , 0x00 , 0x00 , 0x02 , 0x10 , 0x00 , 0x00 , 0x00 , 0x00 , 0x00 , 0x00 ,
	0x00 , 0x00 , 0x00 , 0x00 , 0x00 , 0x00 , 0x00 , 0x00 , 0x04 , 0x10 , 0x00 , 0x00 , 0x00 , 0x00 , 0x00 , 0x00 ,
	0x00 , 0x00 , 0x00 , 0x00 , 0x00 , 0x00 , 0x00 , 0x00 , 0x78 , 0x08 , 0x00 , 0x00 , 0x00 , 0x00 , 0x00 , 0x00 ,
	0x00 , 0x00 , 0x00 , 0x00 , 0x00 , 0x00 , 0x00 , 0x07 , 0x80 , 0x08 , 0x00 , 0x00 , 0x00 , 0x00 , 0x00 , 0x00 ,
	0x00 , 0x00 , 0x00 , 0x00 , 0x00 , 0x00 , 0x00 , 0x18 , 0x00 , 0x04 , 0x00 , 0x00 , 0x00 , 0x00 , 0x00 , 0x00 ,
	0x00 , 0x00 , 0x00 , 0x00 , 0x00 , 0x00 , 0x18 , 0x20 , 0x00 , 0x02 , 0x00 , 0x00 , 0x00 , 0x00 , 0x00 , 0x07 ,
	0x00 , 0x00 , 0x00 , 0x00 , 0x00 , 0x00 , 0x26 , 0x40 , 0x00 , 0x01 , 0x9e , 0x00 , 0x00 , 0x00 , 0x00 , 0x78 ,
	0x00 , 0x00 , 0x00 , 0x00 , 0x00 , 0x00 , 0x41 , 0x80 , 0x00 , 0x00 , 0x61 , 0x00 , 0x00 , 0x00 , 0x07 , 0x80 ,
	0x00 , 0x00 , 0x00 , 0x00 , 0x00 , 0x00 , 0x40 , 0x00 , 0x00 , 0x00 , 0x24 , 0x80 , 0x00 , 0x00 , 0xf8 , 0x00 ,
	0x00 , 0x00 , 0x00 , 0x00 , 0x00 , 0x00 , 0x40 , 0x00 , 0x00 , 0x00 , 0x51 , 0x80 , 0x00 , 0x1f , 0x00 , 0x00 ,
	0x00 , 0x00 , 0x00 , 0x00 , 0x00 , 0x00 , 0x40 , 0x00 , 0x00 , 0x18 , 0x4c , 0x80 , 0x01 , 0xe0 , 0x00 , 0x00 ,
	0x00 , 0x00 , 0x00 , 0x00 , 0x00 , 0x00 , 0x20 , 0x00 , 0x00 , 0x18 , 0x8c , 0x80 , 0x1e , 0x00 , 0x00 , 0x00 ,
	0x00 , 0x00 , 0x00 , 0x00 , 0x00 , 0x00 , 0x20 , 0x00 , 0x00 , 0x00 , 0x80 , 0x81 , 0xe0 , 0x00 , 0x00 , 0x00 ,
	0x00 , 0x00 , 0x00 , 0x00 , 0x00 , 0x00 , 0x20 , 0x73 , 0x00 , 0x40 , 0x81 , 0x1e , 0x00 , 0x00 , 0x00 , 0x00 ,
	0x00 , 0x00 , 0x00 , 0x00 , 0x00 , 0x00 , 0x10 , 0xab , 0x13 , 0xc0 , 0x01 , 0xe0 , 0x00 , 0x00 , 0x00 , 0x00 ,
	0x00 , 0x00 , 0x00 , 0x00 , 0x00 , 0x00 , 0x11 , 0x08 , 0x0c , 0x00 , 0x0e , 0x00 , 0x00 , 0x00 , 0x00 , 0x00 ,
	0x00 , 0x00 , 0x00 , 0x00 , 0x00 , 0x00 , 0x21 , 0x94 , 0x00 , 0x03 , 0xf0 , 0x00 , 0x00 , 0x00 , 0x00 , 0x00 ,
	0x00 , 0x00 , 0x00 , 0x00 , 0x00 , 0x00 , 0x22 , 0x64 , 0x00 , 0x7c , 0x00 , 0x00 , 0x00 , 0x00 , 0x00 , 0x00 ,
	0x00 , 0x00 , 0x00 , 0x00 , 0x00 , 0x00 , 0x42 , 0x64 , 0x07 , 0x80 , 0x00 , 0x00 , 0x00 , 0x00 , 0x00 , 0x00 ,
	0x00 , 0x00 , 0x00 , 0x00 , 0x00 , 0x00 , 0x40 , 0x04 , 0x38 , 0x00 , 0x00 , 0x00 , 0x00 , 0x00 , 0x00 , 0x00 ,
	0x00 , 0x00 , 0x00 , 0x00 , 0x00 , 0x00 , 0x40 , 0x0f , 0xc0 , 0x00 , 0x00 , 0x00 , 0x00 , 0x00 , 0x00 , 0x00 ,
	0x00 , 0x00 , 0x00 , 0x00 , 0x00 , 0x00 , 0x80 , 0x78 , 0x00 , 0x00 , 0x00 , 0x00 , 0x00 , 0x00 , 0x00 , 0x00 ,
	0x00 , 0x00 , 0x00 , 0x00 , 0x00 , 0x00 , 0x9f , 0x80 , 0x00 , 0x00 , 0x00 , 0x00 , 0x00 , 0x00 , 0x00 , 0x00 ,
	0x00 , 0x00 , 0x00 , 0x00 , 0x00 , 0x01 , 0xe0 , 0x00 , 0x00 , 0x00 , 0x00 , 0x00 , 0x00 , 0x00 , 0x00 , 0x00 ,
	0x00 , 0x00 , 0x00 , 0x00 , 0x00 , 0x3e , 0x00 , 0x00 , 0x00 , 0x00 , 0x00 , 0x00 , 0x00 , 0x00 , 0x00 , 0x00 ,
	0x00 , 0x00 , 0x00 , 0x00 , 0x07 , 0xc0 , 0x00 , 0x00 , 0x00 , 0x00 , 0x00 , 0x00 , 0x00 , 0x00 , 0x00 , 0x00 ,
	0x00 , 0x00 , 0x00 , 0x00 , 0x78 , 0x00 , 0x00 , 0x00 , 0x00 , 0x00 , 0x00 , 0x00 , 0x00 , 0x00 , 0x00 , 0x00 ,
	0x00 , 0x00 , 0x00 , 0x07 , 0x80 , 0x00 , 0x00 , 0x00 , 0x00 , 0x00 , 0x00 , 0x00 , 0x00 , 0x00 , 0x00 , 0x00 ,
	0x00 , 0x00 , 0x00 , 0x78 , 0x00 , 0x00 , 0x00 , 0x00 , 0x00 , 0x00 , 0x00 , 0x00 , 0x00 , 0x00 , 0x00 , 0x00 ,
	0x00 , 0x00 , 0x07 , 0x80 , 0x00 , 0x00 , 0x00 , 0x00 , 0x00 , 0x00 , 0x00 , 0x00 , 0x00 , 0x00 , 0x00 , 0x00 ,
	0x00 , 0x00 , 0x78 , 0x00 , 0x00 , 0x00 , 0x00 , 0x00 , 0x00 , 0x00 , 0x00 , 0x00 , 0x00 , 0x00 , 0x00 , 0x00 ,
	0x00 , 0x07 , 0x80 , 0x00 , 0x00 , 0x00 , 0x00 , 0x00 , 0x00 , 0x00 , 0x00 , 0x00 , 0x00 , 0x00 , 0x00 , 0x00 ,
	0x00 , 0x78 , 0x00 , 0x00 , 0x00 , 0x00 , 0x00 , 0x00 , 0x00 , 0x00 , 0x00 , 0x00 , 0x00 , 0x00 , 0x00 , 0x00 ,
	0x07 , 0x80 , 0x00 , 0x00 , 0x00 , 0x00 , 0x00 , 0x00 , 0x00 , 0x00 , 0x00 , 0x00 , 0x00 , 0x00 , 0x00 , 0x00 ,
	0x78 , 0x00 , 0x00 , 0x00 , 0x00 , 0x00 , 0x00 , 0x00 , 0x00 , 0x00 , 0x00 , 0x00 , 0x00 , 0x00 , 0x00 , 0x00 ,
	0x80 , 0x00 , 0x00 , 0x00 , 0x00 , 0x00 , 0x00 , 0x00 , 0x00 , 0x00 , 0x00 , 0x00 , 0x00 , 0x00 , 0x00 , 0x00 ,
	0x00 , 0x00 , 0x00 , 0x00 , 0x00 , 0x00 , 0x00 , 0x00 , 0x00 , 0x00 , 0x00 , 0x00 , 0x00 , 0x00 , 0x00 , 0x00 ,
	0x00 , 0x00 , 0x00 , 0x00 , 0x00 , 0x00 , 0x00 , 0x00 , 0x00 , 0x00 , 0x00 , 0x00 , 0x00 , 0x00 , 0x00 , 0x00 ,
};
/* USER CODE END PV */

void SystemClock_Config(void);
static void MX_GPIO_Init(void);
static void MX_USART1_UART_Init(void);
static void MX_I2C1_Init(void);
static void MX_TIM3_Init(void);
static void MX_TIM1_Init(void);

/* USER CODE BEGIN 0 */
//改变这里的数值调整输出电压
enum speed{
	stop = 0,
	slow = 200,
	medium = 500,
	fast = 1000
};

enum speed leftSpeed = stop;
enum speed rightSpeed = stop;
uint8_t leftDirction = 1;
uint8_t rightDirction = 1;

void SpeedController()
{
	if(leftDirction == 1){
		HAL_GPIO_WritePin(GPIOA, GPIO_PIN_9, 0);
		HAL_GPIO_WritePin(GPIOA, GPIO_PIN_8, 1);
	}
	else if(leftDirction == 0){
		HAL_GPIO_WritePin(GPIOA, GPIO_PIN_9, 1);
		HAL_GPIO_WritePin(GPIOA, GPIO_PIN_8, 0);
	}
	else{
		HAL_GPIO_WritePin(GPIOA, GPIO_PIN_9, 0);
		HAL_GPIO_WritePin(GPIOA, GPIO_PIN_8, 0);
	}
	if(rightDirction == 1){
		HAL_GPIO_WritePin(GPIOB, GPIO_PIN_15, 0);
		HAL_GPIO_WritePin(GPIOB, GPIO_PIN_14, 1);
	}
	else if(rightDirction == 0){
		HAL_GPIO_WritePin(GPIOB, GPIO_PIN_15, 1);
		HAL_GPIO_WritePin(GPIOB, GPIO_PIN_14, 0);
	}
	else{
		HAL_GPIO_WritePin(GPIOB, GPIO_PIN_15, 0);
		HAL_GPIO_WritePin(GPIOB, GPIO_PIN_14, 0);
	}
	__HAL_TIM_SET_COMPARE(&htim1,TIM_CHANNEL_3, leftSpeed);
	__HAL_TIM_SET_COMPARE(&htim3,TIM_CHANNEL_1, rightSpeed);
	HAL_Delay(50);
}
/* USER CODE END 0 */

int main(void)
{

  /* MCU Configuration--------------------------------------------------------*/

  /* Reset of all peripherals, Initializes the Flash interface and the Systick. */
  HAL_Init();

  /* Configure the system clock */
  SystemClock_Config();

  /* Initialize all configured peripherals */
  MX_GPIO_Init();
  MX_USART1_UART_Init();
  MX_I2C1_Init();
  MX_TIM3_Init();
  MX_TIM1_Init();
  /* USER CODE BEGIN 2 */
  SSD1306_Init (); // initialize the display
  __HAL_UART_ENABLE_IT(&huart1,UART_IT_RXNE);

  HAL_TIM_PWM_Start(&htim1, TIM_CHANNEL_3);
  HAL_TIM_PWM_Start(&htim3, TIM_CHANNEL_1);

  HAL_GPIO_WritePin(GPIOA, GPIO_PIN_9, 0);
  HAL_GPIO_WritePin(GPIOA, GPIO_PIN_8, 0);
  HAL_GPIO_WritePin(GPIOB, GPIO_PIN_15, 0);
  HAL_GPIO_WritePin(GPIOB, GPIO_PIN_14, 0);
  /* USER CODE END 2 */

  /* Infinite loop */
  /* USER CODE BEGIN WHILE */
  while (1)
  {
	  SpeedController();
    /* USER CODE END WHILE */
	  SSD1306_Clear();
	  SSD1306_DrawBitmap(0,15,photo1,128,40,1);
	  SSD1306_UpdateScreen();
	  SSD1306_Clear();
	  SSD1306_DrawBitmap(0,15,photo2,128,40,1);
	  SSD1306_UpdateScreen();
	  SSD1306_Clear();
	  SSD1306_DrawBitmap(0,15,photo3,128,40,1);
	  SSD1306_UpdateScreen();
	  SSD1306_Clear();
	  SSD1306_DrawBitmap(0,15,photo4,128,40,1);
	  SSD1306_UpdateScreen();
	  SSD1306_Clear();
	  SSD1306_DrawBitmap(0,15,photo5,128,40,1);
	  SSD1306_UpdateScreen();
	  SSD1306_Clear();
	  SSD1306_DrawBitmap(0,15,photo6,128,40,1);
	  SSD1306_UpdateScreen();
	  SSD1306_Clear();
	  SSD1306_DrawBitmap(0,15,photo7,128,40,1);
	  SSD1306_UpdateScreen();

  }
}

void SystemClock_Config(void)
{
  RCC_OscInitTypeDef RCC_OscInitStruct = {0};
  RCC_ClkInitTypeDef RCC_ClkInitStruct = {0};

  /** Initializes the RCC Oscillators according to the specified parameters
  * in the RCC_OscInitTypeDef structure.
  */
  RCC_OscInitStruct.OscillatorType = RCC_OSCILLATORTYPE_HSE;
  RCC_OscInitStruct.HSEState = RCC_HSE_ON;
  RCC_OscInitStruct.HSEPredivValue = RCC_HSE_PREDIV_DIV1;
  RCC_OscInitStruct.HSIState = RCC_HSI_ON;
  RCC_OscInitStruct.PLL.PLLState = RCC_PLL_ON;
  RCC_OscInitStruct.PLL.PLLSource = RCC_PLLSOURCE_HSE;
  RCC_OscInitStruct.PLL.PLLMUL = RCC_PLL_MUL6;
  if (HAL_RCC_OscConfig(&RCC_OscInitStruct) != HAL_OK)
  {
    Error_Handler();
  }
  /** Initializes the CPU, AHB and APB buses clocks
  */
  RCC_ClkInitStruct.ClockType = RCC_CLOCKTYPE_HCLK|RCC_CLOCKTYPE_SYSCLK
                              |RCC_CLOCKTYPE_PCLK1|RCC_CLOCKTYPE_PCLK2;
  RCC_ClkInitStruct.SYSCLKSource = RCC_SYSCLKSOURCE_PLLCLK;
  RCC_ClkInitStruct.AHBCLKDivider = RCC_SYSCLK_DIV1;
  RCC_ClkInitStruct.APB1CLKDivider = RCC_HCLK_DIV2;
  RCC_ClkInitStruct.APB2CLKDivider = RCC_HCLK_DIV1;

  if (HAL_RCC_ClockConfig(&RCC_ClkInitStruct, FLASH_LATENCY_2) != HAL_OK)
  {
    Error_Handler();
  }
}

static void MX_I2C1_Init(void)
{

  hi2c1.Instance = I2C1;
  hi2c1.Init.ClockSpeed = 400000;
  hi2c1.Init.DutyCycle = I2C_DUTYCYCLE_2;
  hi2c1.Init.OwnAddress1 = 0;
  hi2c1.Init.AddressingMode = I2C_ADDRESSINGMODE_7BIT;
  hi2c1.Init.DualAddressMode = I2C_DUALADDRESS_DISABLE;
  hi2c1.Init.OwnAddress2 = 0;
  hi2c1.Init.GeneralCallMode = I2C_GENERALCALL_DISABLE;
  hi2c1.Init.NoStretchMode = I2C_NOSTRETCH_DISABLE;
  if (HAL_I2C_Init(&hi2c1) != HAL_OK)
  {
    Error_Handler();
  }

}

static void MX_TIM1_Init(void)
{

  TIM_ClockConfigTypeDef sClockSourceConfig = {0};
  TIM_MasterConfigTypeDef sMasterConfig = {0};
  TIM_OC_InitTypeDef sConfigOC = {0};
  TIM_BreakDeadTimeConfigTypeDef sBreakDeadTimeConfig = {0};

  htim1.Instance = TIM1;
  htim1.Init.Prescaler = 72-1;
  htim1.Init.CounterMode = TIM_COUNTERMODE_UP;
  htim1.Init.Period = 100;
  htim1.Init.ClockDivision = TIM_CLOCKDIVISION_DIV1;
  htim1.Init.RepetitionCounter = 0;
  htim1.Init.AutoReloadPreload = TIM_AUTORELOAD_PRELOAD_DISABLE;
  if (HAL_TIM_Base_Init(&htim1) != HAL_OK)
  {
    Error_Handler();
  }
  sClockSourceConfig.ClockSource = TIM_CLOCKSOURCE_INTERNAL;
  if (HAL_TIM_ConfigClockSource(&htim1, &sClockSourceConfig) != HAL_OK)
  {
    Error_Handler();
  }
  if (HAL_TIM_PWM_Init(&htim1) != HAL_OK)
  {
    Error_Handler();
  }
  sMasterConfig.MasterOutputTrigger = TIM_TRGO_RESET;
  sMasterConfig.MasterSlaveMode = TIM_MASTERSLAVEMODE_DISABLE;
  if (HAL_TIMEx_MasterConfigSynchronization(&htim1, &sMasterConfig) != HAL_OK)
  {
    Error_Handler();
  }
  sConfigOC.OCMode = TIM_OCMODE_PWM1;
  sConfigOC.Pulse = 0;
  sConfigOC.OCPolarity = TIM_OCPOLARITY_HIGH;
  sConfigOC.OCNPolarity = TIM_OCNPOLARITY_HIGH;
  sConfigOC.OCFastMode = TIM_OCFAST_ENABLE;
  sConfigOC.OCIdleState = TIM_OCIDLESTATE_RESET;
  sConfigOC.OCNIdleState = TIM_OCNIDLESTATE_RESET;
  if (HAL_TIM_PWM_ConfigChannel(&htim1, &sConfigOC, TIM_CHANNEL_3) != HAL_OK)
  {
    Error_Handler();
  }
  sBreakDeadTimeConfig.OffStateRunMode = TIM_OSSR_DISABLE;
  sBreakDeadTimeConfig.OffStateIDLEMode = TIM_OSSI_DISABLE;
  sBreakDeadTimeConfig.LockLevel = TIM_LOCKLEVEL_OFF;
  sBreakDeadTimeConfig.DeadTime = 0;
  sBreakDeadTimeConfig.BreakState = TIM_BREAK_DISABLE;
  sBreakDeadTimeConfig.BreakPolarity = TIM_BREAKPOLARITY_HIGH;
  sBreakDeadTimeConfig.AutomaticOutput = TIM_AUTOMATICOUTPUT_DISABLE;
  if (HAL_TIMEx_ConfigBreakDeadTime(&htim1, &sBreakDeadTimeConfig) != HAL_OK)
  {
    Error_Handler();
  }
  HAL_TIM_MspPostInit(&htim1);

}

static void MX_TIM3_Init(void)
{

  TIM_ClockConfigTypeDef sClockSourceConfig = {0};
  TIM_MasterConfigTypeDef sMasterConfig = {0};
  TIM_OC_InitTypeDef sConfigOC = {0};

  htim3.Instance = TIM3;
  htim3.Init.Prescaler = 72-1;
  htim3.Init.CounterMode = TIM_COUNTERMODE_UP;
  htim3.Init.Period = 100;
  htim3.Init.ClockDivision = TIM_CLOCKDIVISION_DIV1;
  htim3.Init.AutoReloadPreload = TIM_AUTORELOAD_PRELOAD_DISABLE;
  if (HAL_TIM_Base_Init(&htim3) != HAL_OK)
  {
    Error_Handler();
  }
  sClockSourceConfig.ClockSource = TIM_CLOCKSOURCE_INTERNAL;
  if (HAL_TIM_ConfigClockSource(&htim3, &sClockSourceConfig) != HAL_OK)
  {
    Error_Handler();
  }
  if (HAL_TIM_PWM_Init(&htim3) != HAL_OK)
  {
    Error_Handler();
  }
  sMasterConfig.MasterOutputTrigger = TIM_TRGO_RESET;
  sMasterConfig.MasterSlaveMode = TIM_MASTERSLAVEMODE_DISABLE;
  if (HAL_TIMEx_MasterConfigSynchronization(&htim3, &sMasterConfig) != HAL_OK)
  {
    Error_Handler();
  }
  sConfigOC.OCMode = TIM_OCMODE_PWM1;
  sConfigOC.Pulse = 0;
  sConfigOC.OCPolarity = TIM_OCPOLARITY_HIGH;
  sConfigOC.OCFastMode = TIM_OCFAST_ENABLE;
  if (HAL_TIM_PWM_ConfigChannel(&htim3, &sConfigOC, TIM_CHANNEL_1) != HAL_OK)
  {
    Error_Handler();
  }
  HAL_TIM_MspPostInit(&htim3);

}

static void MX_USART1_UART_Init(void)
{

  huart1.Instance = USART1;
  huart1.Init.BaudRate = 9600;
  huart1.Init.WordLength = UART_WORDLENGTH_8B;
  huart1.Init.StopBits = UART_STOPBITS_1;
  huart1.Init.Parity = UART_PARITY_NONE;
  huart1.Init.Mode = UART_MODE_TX_RX;
  huart1.Init.HwFlowCtl = UART_HWCONTROL_NONE;
  huart1.Init.OverSampling = UART_OVERSAMPLING_16;
  if (HAL_UART_Init(&huart1) != HAL_OK)
  {
    Error_Handler();
  }

}

static void MX_GPIO_Init(void)
{
  GPIO_InitTypeDef GPIO_InitStruct = {0};

  /* GPIO Ports Clock Enable */
  __HAL_RCC_GPIOD_CLK_ENABLE();
  __HAL_RCC_GPIOA_CLK_ENABLE();
  __HAL_RCC_GPIOB_CLK_ENABLE();

  /*Configure GPIO pin Output Level */
  HAL_GPIO_WritePin(GPIOB, GPIO_PIN_14|GPIO_PIN_15, GPIO_PIN_RESET);

  /*Configure GPIO pin Output Level */
  HAL_GPIO_WritePin(GPIOA, GPIO_PIN_8|GPIO_PIN_9, GPIO_PIN_RESET);

  /*Configure GPIO pins : PB14 PB15 */
  GPIO_InitStruct.Pin = GPIO_PIN_14|GPIO_PIN_15;
  GPIO_InitStruct.Mode = GPIO_MODE_OUTPUT_PP;
  GPIO_InitStruct.Pull = GPIO_NOPULL;
  GPIO_InitStruct.Speed = GPIO_SPEED_FREQ_LOW;
  HAL_GPIO_Init(GPIOB, &GPIO_InitStruct);

  /*Configure GPIO pins : PA8 PA9 */
  GPIO_InitStruct.Pin = GPIO_PIN_8|GPIO_PIN_9;
  GPIO_InitStruct.Mode = GPIO_MODE_OUTPUT_PP;
  GPIO_InitStruct.Pull = GPIO_NOPULL;
  GPIO_InitStruct.Speed = GPIO_SPEED_FREQ_LOW;
  HAL_GPIO_Init(GPIOA, &GPIO_InitStruct);

}

/* USER CODE BEGIN 4 */
void HAL_UART_RxCpltCallback(UART_HandleTypeDef *huart)
{
	switch(r){
		case 'A': {	//3前进
			leftSpeed = fast;
			rightSpeed = fast;
			leftDirction = 1;
			rightDirction = 1;
			break;
		}
		case 'B': {	//2前进
			leftSpeed = medium;
			rightSpeed = medium;
			leftDirction = 1;
			rightDirction = 1;
			break;
		}
		case 'C': {	//1前进
			leftSpeed = slow;
			rightSpeed = slow;
			leftDirction = 1;
			rightDirction = 1;
			break;
		}
		case 'D': {	//3后退
			leftSpeed = fast;
			rightSpeed = fast;
			leftDirction = 0;
			rightDirction = 0;
			break;
		}
		case 'E': {	//2后退
			leftSpeed = medium;
			rightSpeed = medium;
			leftDirction = 0;
			rightDirction = 0;
			break;
		}
		case 'F': {	//1后退
			leftSpeed = slow;
			rightSpeed = slow;
			leftDirction = 0;
			rightDirction = 0;
			break;
		}
		case 'G': {	//3左前
			leftSpeed = medium;
			rightSpeed = fast;
			leftDirction = 1;
			rightDirction = 1;
			break;
			}
		case 'H': {	//2左前
			leftSpeed = slow;
			rightSpeed = medium;
			leftDirction = 1;
			rightDirction = 1;
			break;
		}
		case 'I': {	//1左前
			leftSpeed = stop;
			rightSpeed = slow;
			leftDirction = 3;
			rightDirction = 1;
			break;
		}
		case 'J': {	//3左后
			leftSpeed = medium;
			rightSpeed = fast;
			leftDirction = 0;
			rightDirction = 0;
			break;
		}
		case 'K': {	//2左后
			leftSpeed = slow;
			rightSpeed = medium;
			leftDirction = 0;
			rightDirction = 0;
			break;
		}
		case 'L': {	//1左后
			leftSpeed = stop;
			rightSpeed = slow;
			leftDirction = 3;
			rightDirction = 0;
			break;
		}
		case 'M': {	//3右前
			leftSpeed = fast;
			rightSpeed = medium;
			leftDirction = 1;
			rightDirction = 1;
			break;
		}
		case 'N': {	//2右前
			leftSpeed = medium;
			rightSpeed = slow;
			leftDirction = 1;
			rightDirction = 1;
			break;
		}
		case 'O': {	//1右前
			leftSpeed = slow;
			rightSpeed = stop;
			leftDirction = 1;
			rightDirction = 3;
			break;
		}
		case 'P': {	//3右后
			leftSpeed = fast;
			rightSpeed = medium;
			leftDirction = 0;
			rightDirction = 0;
			break;
		}
		case 'Q': {	//2右后
			leftSpeed = medium;
			rightSpeed = slow;
			leftDirction = 0;
			rightDirction = 0;
			break;
		}
		case 'R': {	//1右后
			leftSpeed = slow;
			rightSpeed = stop;
			leftDirction = 0;
			rightDirction = 3;
			break;
		}
		case 'S': {	//逆时针原地旋转
			leftSpeed = slow;
			rightSpeed = slow;
			leftDirction = 0;
			rightDirction = 1;
			break;
		}
		case 'T': {	//顺时针原地旋转
			leftSpeed = slow;
			rightSpeed = slow;
			leftDirction = 1;
			rightDirction = 0;
			break;
		}
		default : {	//停下
			leftSpeed = stop;
			rightSpeed = stop;
			leftDirction = 3;
			rightDirction = 3;
		}
	}
}
/* USER CODE END 4 */

void Error_Handler(void)
{
  __disable_irq();
  while (1)
  {
  }
}
